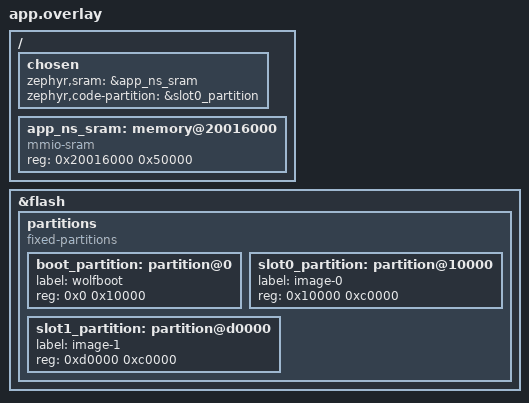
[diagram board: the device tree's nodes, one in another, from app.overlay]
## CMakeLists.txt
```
cmake_minimum_required(VERSION 3.20.0)

# ── wolfBoot module path ───────────────────────────────────────────────────────
if(NOT "$ENV{ZEPHYR_BASE}" STREQUAL "")
    set(_wb_zbase "$ENV{ZEPHYR_BASE}")
elseif(NOT "${ZEPHYR_BASE}" STREQUAL "")
    set(_wb_zbase "${ZEPHYR_BASE}")
else()
    message(FATAL_ERROR
        "ZEPHYR_BASE is not set. "
        "Run cmake with --preset debug or export ZEPHYR_BASE in the environment.")
endif()
get_filename_component(WOLFBOOT_MODULE_DIR
    "${_wb_zbase}/../modules/bootloader/wolfboot" ABSOLUTE)
get_filename_component(_ZEPHYRPROJECT_DIR "${_wb_zbase}/.." ABSOLUTE)

set(_MCUX_ROOT    "${_ZEPHYRPROJECT_DIR}/modules/hal/nxp/mcux/mcux-sdk-ng")
set(_MCUX_CMSIS   "${_ZEPHYRPROJECT_DIR}/modules/hal/cmsis_6/CMSIS")
set(_MCUX_DRV     "${_MCUX_ROOT}/devices/MCX/MCXN/MCXN947")
set(_MCUX_TMPL    "${CMAKE_SOURCE_DIR}/wolfbootConfig")
set(_WOLFSSL_ROOT "${_ZEPHYRPROJECT_DIR}/modules/crypto/wolfssl")

# ── Apply wolfBoot board patch (idempotent, configure time) ───────────────────
set(_WB_PATCH "${CMAKE_SOURCE_DIR}/wolfbootConfig/0001-Update-configs-and-memory-map.patch")
execute_process(
    COMMAND git apply --check --reverse "${_WB_PATCH}"
    WORKING_DIRECTORY "${WOLFBOOT_MODULE_DIR}"
    RESULT_VARIABLE _patch_applied
    OUTPUT_QUIET ERROR_QUIET
)
if(NOT _patch_applied EQUAL 0)
    execute_process(
        COMMAND git apply "${_WB_PATCH}"
        WORKING_DIRECTORY "${WOLFBOOT_MODULE_DIR}"
        RESULT_VARIABLE _patch_result
        ERROR_VARIABLE  _patch_error
    )
    if(NOT _patch_result EQUAL 0)
        message(FATAL_ERROR
            "Failed to apply wolfBoot patch\n"
            "  patch:   ${_WB_PATCH}\n"
            "  workdir: ${WOLFBOOT_MODULE_DIR}\n"
            "  git output: ${_patch_error}")
    endif()
endif()
set(_WB_PATCHES "${_WB_PATCH}")

# wolfBoot cross compiler: CROSS_COMPILE, else the Zephyr SDK, else arm-none-eabi-gcc.
set(_WB_CROSS "")
if(DEFINED ENV{CROSS_COMPILE} AND NOT "$ENV{CROSS_COMPILE}" STREQUAL "")
    set(_WB_CROSS "$ENV{CROSS_COMPILE}")
elseif((DEFINED ENV{ZEPHYR_TOOLCHAIN_VARIANT} AND
        ("$ENV{ZEPHYR_TOOLCHAIN_VARIANT}" STREQUAL "zephyr" OR
         "$ENV{ZEPHYR_TOOLCHAIN_VARIANT}" STREQUAL "zephyr-sdk")) OR
       DEFINED ENV{ZEPHYR_SDK_INSTALL_DIR})
    set(_WB_SDK "$ENV{ZEPHYR_SDK_INSTALL_DIR}")
    # SDK >= 1.0 keeps toolchains in <sdk>/gnu/<triplet>, older ones in <sdk>/<triplet>.
    foreach(_WB_SDK_CANDIDATE
            "${_WB_SDK}/gnu/arm-zephyr-eabi/bin/arm-zephyr-eabi-"
            "${_WB_SDK}/arm-zephyr-eabi/bin/arm-zephyr-eabi-")
        if(EXISTS "${_WB_SDK_CANDIDATE}gcc")
            set(_WB_CROSS "${_WB_SDK_CANDIDATE}")
            break()
        endif()
    endforeach()
    if("${_WB_CROSS}" STREQUAL "")
        message(FATAL_ERROR
            "ZEPHYR_TOOLCHAIN_VARIANT is the Zephyr SDK but no arm-zephyr-eabi "
            "toolchain was found under ZEPHYR_SDK_INSTALL_DIR='${_WB_SDK}'.\n"
            "Install the Zephyr SDK with the arm-zephyr-eabi GNU toolchain, or "
            "set CROSS_COMPILE to a cross compiler prefix.")
    endif()
else()
    find_program(_WB_HOST_GCC arm-none-eabi-gcc)
    if(_WB_HOST_GCC)
        set(_WB_CROSS "arm-none-eabi-")
    else()
        message(FATAL_ERROR
            "No Arm cross compiler for wolfBoot. Either install the Zephyr SDK "
            "(and set ZEPHYR_SDK_INSTALL_DIR, with "
            "ZEPHYR_TOOLCHAIN_VARIANT=zephyr on Zephyr >= 4.3 or zephyr-sdk on "
            "older releases), put arm-none-eabi-gcc in PATH, or set "
            "CROSS_COMPILE. Twister and the Zephyr CI containers both use only "
            "the Zephyr SDK.")
    endif()
endif()
message(STATUS "wolfBoot cross compiler: ${_WB_CROSS}gcc")

# Use the cross strip: the host strip can't handle a Cortex-M33 ELF.
set(_WB_STRIP "strip")
if(DEFINED ENV{CONFIG_STRIP} AND NOT "$ENV{CONFIG_STRIP}" STREQUAL "")
    set(_WB_STRIP "$ENV{CONFIG_STRIP}")
elseif(EXISTS "${_WB_CROSS}strip")
    set(_WB_STRIP "${_WB_CROSS}strip")
endif()
message(STATUS "wolfBoot strip: ${_WB_STRIP}")

# Wipe wolfBoot objects when the compiler or patches change (make only checks timestamps).
set(_WB_STAMP_SRC "${_WB_CROSS}")
foreach(_WB_PATCH IN LISTS _WB_PATCHES)
    file(SHA1 "${_WB_PATCH}" _wb_patch_sha)
    string(APPEND _WB_STAMP_SRC "|${_WB_PATCH}=${_wb_patch_sha}")
endforeach()
string(SHA1 _WB_STAMP "${_WB_STAMP_SRC}")
set(_WB_STAMP_FILE "${WOLFBOOT_MODULE_DIR}/.zephyr-app-build-stamp")
set(_WB_STAMP_OLD "")
if(EXISTS "${_WB_STAMP_FILE}")
    file(READ "${_WB_STAMP_FILE}" _WB_STAMP_OLD)
endif()
if(NOT _WB_STAMP_OLD STREQUAL _WB_STAMP)
    message(STATUS "wolfBoot: toolchain/patches changed, removing stale objects")
    execute_process(
        COMMAND make clean
        WORKING_DIRECTORY "${WOLFBOOT_MODULE_DIR}"
        RESULT_VARIABLE _wb_clean
        OUTPUT_QUIET ERROR_QUIET
    )
    file(GLOB_RECURSE _WB_STALE_OBJS
         "${_MCUX_ROOT}/*.o" "${_MCUX_DRV}/*.o" "${_MCUX_TMPL}/*.o")
    if(_WB_STALE_OBJS)
        list(FILTER _WB_STALE_OBJS EXCLUDE REGEX "${CMAKE_BINARY_DIR}")
        # file(REMOVE) with no arguments errors before CMake 3.31.
        file(REMOVE ${_WB_STALE_OBJS})
    endif()
endif()

# ── wolfBoot binary build (configure time, before Zephyr) ─────────────────────
# CORTEX_M33=1 must be on the command line so the ifeq in arch.mk (~line 357)
# is evaluated true during Makefile parse. arch.mk sets CORTEX_M33=1 for mcxn
# only at ~line 834, which is too late for the parse-time ifeq. Without this,
# -mcmse is never added to CFLAGS and --cmse-implib is never added to
# SECURE_LDFLAGS, so libwolfboot.o lacks SG stubs and wolfboot_tz_nsc.o is
# never emitted by the linker.
# If wolfboot_tz_nsc.o is absent, remove libwolfboot.o (the only object with
# CMSE entry functions) and the stale elf/bin so make recompiles and relinks.
if(NOT EXISTS "${WOLFBOOT_MODULE_DIR}/src/wolfboot_tz_nsc.o")
    file(REMOVE
        "${WOLFBOOT_MODULE_DIR}/src/libwolfboot.o"
        "${WOLFBOOT_MODULE_DIR}/wolfboot.elf"
        "${WOLFBOOT_MODULE_DIR}/wolfboot.bin"
    )
endif()
execute_process(
    COMMAND make wolfboot.bin keytools tools/bin-assemble/bin-assemble
        WOLFBOOT_ROOT=${WOLFBOOT_MODULE_DIR}
        TARGET=mcxn ARCH=ARM TZEN=1 SIGN=ECC384 HASH=SHA384
        CORTEX_M33=1
        CROSS_COMPILE=${_WB_CROSS}
        CONFIG_STRIP=${_WB_STRIP}
        MCUXSDK=1
        # NDEBUG: the MCUX drivers' asserts need stderr/_exit, which a bootloader lacks.
        CFLAGS_EXTRA=-DNDEBUG=1
        MCUXPRESSO=${_MCUX_ROOT}
        MCUXPRESSO_CMSIS=${_MCUX_CMSIS}
        MCUXPRESSO_CPU=MCXN947VDF_cm33_core0
        MCUXPRESSO_DRIVERS=${_MCUX_DRV}
        MCUXPRESSO_PROJECT_TEMPLATE=${_MCUX_TMPL}
        WOLFBOOT_LIB_WOLFSSL=${_WOLFSSL_ROOT}
        NO_MPU=1 NVM_FLASH_WRITEONCE=1 SPMATH=1 RAM_CODE=1 PKA=1 DEBUG_UART=1
        NO_ARM_ASM=1 WOLFBOOT_VERSION=0
        WOLFBOOT_SECTOR_SIZE=0x2000
        WOLFBOOT_KEYVAULT_ADDRESS=0x1000D000 WOLFBOOT_KEYVAULT_SIZE=0
        WOLFBOOT_NSC_ADDRESS=0x1000E000 WOLFBOOT_NSC_SIZE=0x1000
        WOLFBOOT_PARTITION_SIZE=0xC0000
        WOLFBOOT_PARTITION_BOOT_ADDRESS=0x10000
        WOLFBOOT_PARTITION_UPDATE_ADDRESS=0xD0000
        WOLFBOOT_PARTITION_SWAP_ADDRESS=0x190000
        IMAGE_HEADER_SIZE=1024
    WORKING_DIRECTORY "${WOLFBOOT_MODULE_DIR}"
    RESULT_VARIABLE _wb_result
)
if(NOT _wb_result EQUAL 0)
    message(FATAL_ERROR "wolfBoot make failed")
endif()
file(WRITE "${_WB_STAMP_FILE}" "${_WB_STAMP}")

file(MAKE_DIRECTORY "${CMAKE_BINARY_DIR}/zephyr")
file(COPY "${WOLFBOOT_MODULE_DIR}/wolfboot.bin"
          "${WOLFBOOT_MODULE_DIR}/wolfboot.elf"
     DESTINATION "${CMAKE_BINARY_DIR}/zephyr")

# ── Default board + overlay so no CMakePresets.json edit is required ───────────
# This application runs in the non-secure world and is booted by wolfBoot in the
# secure world: it links the wolfBoot NSC veneer (wolfboot_tz_nsc.o), defines
# TZEN, and uses system_init_ns.c. On FRDM-MCXN947 it must be built for the /ns
# board variant -- a secure (non-/ns) build still links and signs, but wolfBoot
# hands off to the wrong memory map / vector table and the app faults at boot
# (garbled UART, never reaches the Zephyr banner). Default board and overlay here
# so the stock build needs no preset edit; an explicit override is still honored
# for porting to other boards.
set(_DEFAULT_BOARD "frdm_mcxn947/mcxn947/cpu0/ns")
set(_SECURE_BOARD  "frdm_mcxn947/mcxn947/cpu0")  # non-bootable secure variant pinned by mistake
if(NOT DEFINED BOARD OR "${BOARD}" STREQUAL "")
    set(BOARD "${_DEFAULT_BOARD}" CACHE STRING "Target board" FORCE)
elseif("${BOARD}" STREQUAL "${_SECURE_BOARD}")
    message(WARNING
        "BOARD='${BOARD}' is the secure variant and will not boot under wolfBoot; "
        "forcing '${_DEFAULT_BOARD}'. (Delete the build dir if it was already "
        "configured for the secure board.)")
    set(BOARD "${_DEFAULT_BOARD}" CACHE STRING "Target board" FORCE)
elseif(NOT "${BOARD}" STREQUAL "${_DEFAULT_BOARD}")
    message(WARNING
        "BOARD='${BOARD}' overrides the default '${_DEFAULT_BOARD}'. On "
        "FRDM-MCXN947 the app is non-secure-world only and a non-/ns build will "
        "not boot under wolfBoot; ignore this if you are porting to another board.")
endif()
if(NOT DEFINED DTC_OVERLAY_FILE OR "${DTC_OVERLAY_FILE}" STREQUAL "")
    set(DTC_OVERLAY_FILE "${CMAKE_SOURCE_DIR}/app.overlay"
        CACHE STRING "Devicetree overlay" FORCE)
endif()

# ── Normal Zephyr app build ───────────────────────────────────────────────────
find_package(Zephyr REQUIRED HINTS $ENV{ZEPHYR_BASE})
project(wolfssl-ota-client)

if(NOT EXISTS "${CMAKE_SOURCE_DIR}/__repo__")
    execute_process(
        COMMAND ${CMAKE_COMMAND} -E create_symlink
            $ENV{ZEPHYR_BASE}/.. ${CMAKE_SOURCE_DIR}/__repo__
        COMMAND_ECHO STDOUT)
endif()

target_sources(app PRIVATE src/main.c)
target_sources(app PRIVATE src/system_init_ns.c)
target_sources(app PRIVATE __repo__/modules/crypto/wolfssl/wolfcrypt/test/test.c)
target_sources(app PRIVATE __repo__/modules/crypto/wolfssl/wolfcrypt/benchmark/benchmark.c)
target_include_directories(app PRIVATE src)

target_sources(app PRIVATE src/mqttClient/fwclient.c)
target_sources(app PRIVATE src/mqttClient/mqttexample.c)
target_sources(app PRIVATE src/mqttClient/mqttnet.c)
target_sources(app PRIVATE src/mqttClient/mqttport.c)
target_include_directories(app PRIVATE src/mqttClient)
target_compile_definitions(app PRIVATE WOLFMQTT_USER_SETTINGS)

add_definitions(-DWOLFSSL_USER_SETTINGS)

target_compile_definitions(app PRIVATE TZEN)
target_link_libraries(app PRIVATE "${WOLFBOOT_MODULE_DIR}/src/wolfboot_tz_nsc.o")
target_include_directories(app PRIVATE "${WOLFBOOT_MODULE_DIR}/include")

# ── Auto strip + sign after every build ───────────────────────────────────────
set(_SIGN_TOOL       "${WOLFBOOT_MODULE_DIR}/tools/keytools/sign")
set(_SIGN_KEY        "${WOLFBOOT_MODULE_DIR}/wolfboot_signing_private_key.der")
set(_ZEPHYR_ELF      "${CMAKE_BINARY_DIR}/zephyr/zephyr.elf")
set(_ZEPHYR_BIN      "${CMAKE_BINARY_DIR}/zephyr/zephyr.bin")
set(_ZEPHYR_STRIPPED "${CMAKE_BINARY_DIR}/zephyr/zephyr_stripped.bin")

add_custom_target(sign_images ALL
    COMMENT "Strip header and sign wolfBoot images (v1, v2)"
    COMMAND ${CMAKE_OBJCOPY}
        --gap-fill 0xFF --output-target=binary
        --remove-section=.comment --remove-section=COMMON
        "${_ZEPHYR_ELF}" "${_ZEPHYR_BIN}"
    COMMAND dd "if=${_ZEPHYR_BIN}" "of=${_ZEPHYR_STRIPPED}" bs=1 skip=1024
    COMMAND ${CMAKE_COMMAND} -E env "IMAGE_HEADER_SIZE=1024"
        "${_SIGN_TOOL}" --ecc384 --sha384 "${_ZEPHYR_STRIPPED}" "${_SIGN_KEY}" 1
    COMMAND ${CMAKE_COMMAND} -E env "IMAGE_HEADER_SIZE=1024"
        "${_SIGN_TOOL}" --ecc384 --sha384 "${_ZEPHYR_STRIPPED}" "${_SIGN_KEY}" 2
    VERBATIM
)
add_dependencies(sign_images zephyr_final)

# ── Factory image (wolfboot + signed app) ─────────────────────────────────────
set(_BIN_ASSEMBLE "${WOLFBOOT_MODULE_DIR}/tools/bin-assemble/bin-assemble")
set(_FACTORY_BIN  "${CMAKE_BINARY_DIR}/zephyr/factory.bin")

add_custom_target(factory_bin ALL
    COMMENT "Assemble factory image: wolfboot at 0x0, signed app at 0x10000"
    COMMAND "${_BIN_ASSEMBLE}"
        "${_FACTORY_BIN}"
        0x0     "${CMAKE_BINARY_DIR}/zephyr/wolfboot.bin"
        0x10000 "${CMAKE_BINARY_DIR}/zephyr/zephyr_stripped_v1_signed.bin"
    VERBATIM
)
add_dependencies(factory_bin sign_images)
```

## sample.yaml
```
sample:
  description: An OTA client that uses the ethernet available on the FRDM-MCXN947 and is
    updated by a wolfBoot secure bootloader
  name: OTA Client with wolfSSL and wolfBoot
tests:
  sample.wolfssl.ota_client:
    # Needs wolfBoot in flash and an MQTT broker, so CI only builds it.
    build_only: true
    tags:
      - net
      - eth
      - tls
      - wolfssl
      - wolfboot
      - ota
    # Boots as /ns under wolfBoot; plain cpu0 is allowed so twister -p cpu0 still builds it.
    platform_allow:
      - frdm_mcxn947/mcxn947/cpu0
      - frdm_mcxn947/mcxn947/cpu0/ns
    integration_platforms:
      - frdm_mcxn947/mcxn947/cpu0/ns
```

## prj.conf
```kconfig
CONFIG_UART_CONSOLE=y

# Link and flash the application into the board-defined code partition
# (slot0_partition at 0x10010000 on FRDM-MCXN947).
CONFIG_USE_DT_CODE_PARTITION=y

# Reserve 0x200 bytes at the start of the code partition for an image header.
CONFIG_ROM_START_OFFSET=0x200

# Linker base remap: use alias addresses instead of physical bus addresses.
CONFIG_FLASH_BASE_ADDRESS=0x0
CONFIG_SRAM_BASE_ADDRESS=0x20016000

# Clock for time()
CONFIG_CLOCK_CONTROL=y

# Log settings. Using immediate mode to not drop bursty logs
CONFIG_LOG=y
CONFIG_LOG_PRINTK=n

# Enable float support for printf/printk
CONFIG_CBPRINTF_FP_SUPPORT=y

CONFIG_MAIN_STACK_SIZE=32768

CONFIG_ASSERT=y

# POSIX Settings
CONFIG_POSIX_API=y

# Network settings
CONFIG_NETWORKING=y
CONFIG_NET_CONFIG_SETTINGS=y
CONFIG_NET_CONFIG_AUTO_INIT=n
CONFIG_NET_CONFIG_NEED_IPV4=n
CONFIG_NET_DHCPV4=n
CONFIG_NET_L2_ETHERNET=y
CONFIG_NET_IPV6=n
CONFIG_NET_CONFIG_NEED_IPV6=n
CONFIG_NET_IPV4=y
CONFIG_NET_SOCKETS=y
CONFIG_NET_TCP=y 
CONFIG_DNS_RESOLVER=y

# Disable Flash API as the flash operations are handled by wolfBoot NSC APIs.
CONFIG_FLASH=n
CONFIG_SOC_FLASH_MCUX=n
# TLS configuration

CONFIG_WOLFSSL=y
CONFIG_WOLFSSL_BUILTIN=y
CONFIG_WOLFSSL_DEBUG=n
# TLS versions are set in src/user_settings.h (the Kconfig ones need no settings file).

# MQTT configuration
CONFIG_WOLFMQTT=y
CONFIG_WOLFMQTT_TLS=y
# Enable wolfMQTT user settings to adjust the configuration as same as wolfSSL
CONFIG_WOLFMQTT_SETTINGS_FILE="user_settings.h"

# CONFIG_NET_BUF_DATA_SIZE=512
CONFIG_NET_BUF_DATA_SIZE=1536

CONFIG_ENTROPY_GENERATOR=y
CONFIG_TEST_RANDOM_GENERATOR=y

#ETHERNET
CONFIG_ETH_NXP_ENET_QOS=y
CONFIG_ETH_NXP_ENET_QOS_MAC=y

CONFIG_WOLFSSL_SETTINGS_FILE="user_settings.h"

# For debug
CONFIG_DEBUG_OPTIMIZATIONS=n

CONFIG_REBOOT=y

# TrustZone settings
# Build this Zephyr image for Non-Secure state execution.
CONFIG_TRUSTED_EXECUTION_SECURE=n
CONFIG_TRUSTED_EXECUTION_NONSECURE=y

# Early SoC init hook: FPU/PowerQuad coprocessor access, ECC, flash cache,
# and aGDET setup for NS world (replaces SystemInit() which now skips NS).
CONFIG_SOC_EARLY_INIT_HOOK=y

# NS board defconfig enables TF-M; this project uses wolfBoot on the secure side.
CONFIG_BUILD_WITH_TFM=n
```

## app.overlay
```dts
/*
 * Upstream cpu0/ns board targets TF-M: chosen points at slot0_ns_partition (256 KiB flash)
 * and non_secure_ram (128 KiB). This app runs under wolfBoot with a different map; see
 * wolfbootConfig/.config and hal/mcxn.c SAU (0x20016000 .. 0x20065FFF).
 */

/ {
	chosen {
		zephyr,sram = &app_ns_sram;
		zephyr,code-partition = &slot0_partition;
	};

	/* NS-visible SRAM for the Zephyr image (must match wolfBoot SAU). */
	app_ns_sram: memory@20016000 {
		compatible = "mmio-sram";
		reg = <0x20016000 0x50000>; /* 320 KiB */
	};
};

/* Drop TF-M flash layout; replace with wolfBoot partition table from wolfbootConfig/.config */
&flash {
	/delete-node/ partitions;
};

&flash {
	partitions {
		compatible = "fixed-partitions";
		#address-cells = <1>;
		#size-cells = <1>;

		boot_partition: partition@0 {
			label = "wolfboot";
			reg = <0x0 0x10000>;
		};

		slot0_partition: partition@10000 {
			label = "image-0";
			reg = <0x10000 0xc0000>;
		};

		slot1_partition: partition@d0000 {
			label = "image-1";
			reg = <0xd0000 0xc0000>;
		};
	};
};
```

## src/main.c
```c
/* main.c
 *
 * Copyright (C) 2006-2024 wolfSSL Inc.
 *
 * This file is part of wolfSSL.
 *
 * wolfSSL is free software; you can redistribute it and/or modify
 * it under the terms of the GNU General Public License as published by
 * the Free Software Foundation; either version 2 of the License, or
 * (at your option) any later version.
 *
 * wolfSSL is distributed in the hope that it will be useful,
 * but WITHOUT ANY WARRANTY; without even the implied warranty of
 * MERCHANTABILITY or FITNESS FOR A PARTICULAR PURPOSE.  See the
 * GNU General Public License for more details.
 *
 * You should have received a copy of the GNU General Public License
 * along with this program; if not, write to the Free Software
 * Foundation, Inc., 51 Franklin Street, Fifth Floor, Boston, MA 02110-1335, USA
 */

/* wolfSSL Includes Start */
/* POSIX socket prototypes come from Zephyr; include them before wolfSSL. */
#include <sys/socket.h>
#include <unistd.h>

#include "user_settings.h"      /* For wolfSSL Zephyr configuration */
#include <wolfssl/wolfcrypt/settings.h>
#include <wolfssl/ssl.h>        /* Basic functionality for TLS */
#include <wolfssl/certs_test.h> /* Needed for Cert Buffers */
#include <wolfssl/wolfcrypt/hash.h>
/* wolfSSL Includes End */

#ifdef WOLFCRYPT_TEST
#include <wolfcrypt/test/test.h>
#endif

#ifdef WOLFCRYPT_BENCHMARK
#include <wolfcrypt/benchmark/benchmark.h>
#endif

/* Standard Packages Start */
#include <stdio.h>
#include <time.h>
#include <string.h>
/* Standard Packages End */

/* Zephyr Includes Start */
#include <zephyr/kernel.h>
#include <zephyr/drivers/gpio.h>
#include <zephyr/net/net_if.h>
#include <zephyr/net/dhcpv4.h>
#include <zephyr/net/net_core.h>
#include <zephyr/net/net_context.h>
#include <zephyr/net/net_mgmt.h>
#include <zephyr/net/net_config.h>
#include <zephyr/net/net_ip.h>
#include <zephyr/sys/reboot.h>
/* Zephyr Includes End */

/* mqttClient Includes Start */
#include "mqttClient/fwclient.h"
/* mqttClient Includes End */

/* wolfBoot Includes Start */
#include "wolfboot/wolfboot.h"
#include "wolfboot_status.h"
/* wolfBoot Includes End */

volatile boot_state_t g_boot_state         = BOOT_STATE_UNKNOWN;
volatile uint32_t     g_boot_version       = 0;
volatile uint32_t     g_update_version     = 0;
volatile uint8_t      g_boot_state_byte    = 0xAA;
volatile int          g_boot_state_rc      = -1;
volatile uint8_t      g_update_state_byte  = 0xAA;
volatile int          g_update_state_rc    = -1;

/* Program Defines Start */

#define DEFAULT_PORT 11111  /* Define the port we want to use for the network */

#define LOCAL_DEBUG 0       /* Use for wolfSSL's internal Debugging */

/* Use DHCP auto IP assignment or static assignment.
 * Follows CONFIG_NET_DHCPV4 from prj.conf so both stay in sync. */
#undef  DHCP_ON
#ifdef CONFIG_NET_DHCPV4
    #define DHCP_ON 1
#else
    #define DHCP_ON 0
#endif
 
#if DHCP_ON == 0
/* Define Static IP, Gateway, and Netmask */
    #define STATIC_IPV4_ADDR  "192.168.1.70"
    #define STATIC_IPV4_GATEWAY "192.168.1.1"
    #define STATIC_IPV4_NETMASK "255.255.255.0"
#endif

/* Set the TLS Version. Currently only 2 or 3 is available for this */
/* application, defaults to TLSv3 */
#undef TLS_VERSION
#define TLS_VERSION 3

/* This sets up the correct function for the application via macros */
#undef TLS_METHOD
#if TLS_VERSION == 3
    #define TLS_METHOD wolfTLSv1_3_server_method()
#elif TLS_VERSION == 2
    #define TLS_METHOD wolfTLSv1_2_server_method()
#else 
    #define TLS_METHOD wolfTLSv1_3_server_method()
#endif

/* Set up the network using the Zephyr network stack */
int startNetwork() {

    struct net_if *iface = net_if_get_default();
    char buf[NET_IPV4_ADDR_LEN];

    #if DHCP_ON == 0
        struct in_addr addr, netmask, gw;
    #endif

    if (!(iface)) { /* See if a network interface (ethernet) is available */
        printf("No network interface determined");
        return 1;
    }

    if (net_if_flag_is_set(iface, NET_IF_DORMANT)) {
        printf("Waiting on network interface to be available");
        while(!net_if_is_up(iface)){
            k_sleep(K_MSEC(100));
        }
    }

    #if DHCP_ON == 1
        printf("\nStarting DHCP to obtain IP address\n");
        net_dhcpv4_start(iface);
        (void)net_mgmt_event_wait_on_iface(iface, NET_EVENT_IPV4_DHCP_BOUND, \
                                            NULL, NULL, NULL, K_FOREVER);
    #elif DHCP_ON == 0
        /* Static IP Configuration */
        if (net_addr_pton(AF_INET, STATIC_IPV4_ADDR, &addr) < 0 ||
            net_addr_pton(AF_INET, STATIC_IPV4_NETMASK, &netmask) < 0 ||
            net_addr_pton(AF_INET, STATIC_IPV4_GATEWAY, &gw) < 0) {
            printf("Invalid IP address settings.\n");
            return -1;
        }
        net_if_ipv4_set_netmask_by_addr(iface, &addr, &netmask);
        net_if_ipv4_set_gw(iface, &gw);
        net_if_ipv4_addr_add(iface, &addr, NET_ADDR_MANUAL, 0);

    #else
        #error "Please set DHCP_ON to true (1) or false (0), if unsure set to true (1)"
    #endif

    /* Display IP address that was assigned when done */
    printf("IP Address is: %s", net_addr_ntop(AF_INET, \
                    &iface->config.ip.ipv4->unicast[0].ipv4.address.in_addr, \
                    buf, sizeof(buf)));

    return 0;
}

/* Initialize Server for a client connection */
int startServer(void) {
    int                sockfd = SOCKET_INVALID;
    int                connd = SOCKET_INVALID;
    struct sockaddr_in servAddr;
    struct sockaddr_in clientAddr;
    socklen_t          size = sizeof(clientAddr);
    char               buff[256];
    size_t             len;
    int                shutdown = 0;
    int                ret;
    const char*        reply = "I hear ya fa shizzle!\n";

    WOLFSSL_CTX* ctx = NULL;
    WOLFSSL*     ssl = NULL;
    WOLFSSL_CIPHER* cipher;

    #if LOCAL_DEBUG
        wolfSSL_Debugging_ON();
    #endif

    wolfSSL_Init();

    /* Create a socket that uses an internet IPv4 address,
     * Sets the socket to be stream based (TCP),
     * 0 means choose the default protocol. */
    if ((sockfd = socket(AF_INET, SOCK_STREAM, 0)) == -1) {
        printf("\nERROR: failed to create the socket\n");
        return 1;
    }

    ctx = wolfSSL_CTX_new(TLS_METHOD);
    if (ctx == NULL) {
        printf("\nERROR: Failed to create WOLFSSL_CTX\n");
        return 1;
    }

    if (wolfSSL_CTX_use_certificate_chain_buffer_format(ctx,
                server_cert_der_2048, sizeof_server_cert_der_2048,
                WOLFSSL_FILETYPE_ASN1) != WOLFSSL_SUCCESS){
        printf("\nERROR: Cannot load server cert buffer\n");
        return 1; 
    }

    if (wolfSSL_CTX_use_PrivateKey_buffer(ctx, server_key_der_2048,
            sizeof_server_key_der_2048, SSL_FILETYPE_ASN1) != WOLFSSL_SUCCESS){
        printf("\nERROR: Can't load server private key buffer");
        return 1;
    }

    /* Initialize the server address struct with zeros */
    memset(&servAddr, 0, sizeof(servAddr));

    /* Fill in the server address */
    servAddr.sin_family      = AF_INET;             /* using IPv4      */
    servAddr.sin_port        = htons(DEFAULT_PORT); /* on DEFAULT_PORT */
    servAddr.sin_addr.s_addr = INADDR_ANY;          /* from anywhere   */

    /* Bind the server socket to our port */
    if (bind(sockfd, (struct sockaddr*)&servAddr, sizeof(servAddr)) == -1) {
        printf("\nERROR: failed to bind\n");
        return 1;
    }

    /* Listen for a new connection, allow 5 pending connections */
    if (listen(sockfd, 5) == -1) {
        printf("\nERROR: failed to listen\n");
        return 1;
    } 

    printf("\nServer Started\n");

    /* Continue to accept clients until shutdown is issued */
    while (!shutdown) {
        printf("Waiting for a connection...\n");

        /* Accept client connections */
        if ((connd = accept(sockfd, (struct sockaddr*)&clientAddr, &size))
            == -1) {
            printf("\nERROR: failed to accept the connection\n");
            return 1;
        }

        /* Create a WOLFSSL object */
        if ((ssl = wolfSSL_new(ctx)) == NULL) {
            printf("\nERROR: failed to create WOLFSSL object\n");
            return 1;
        }

        /* Attach wolfSSL to the socket */
        wolfSSL_set_fd(ssl, connd);

        /* Establish TLS connection */
        ret = wolfSSL_accept(ssl);
        if (ret != WOLFSSL_SUCCESS) {
            printf("\nERROR: wolfSSL_accept error = %d\n",
                wolfSSL_get_error(ssl, ret));
            return 1;
        }


        printf("Client connected successfully\n");

        cipher = wolfSSL_get_current_cipher(ssl);
        printf("SSL cipher suite is %s\n", wolfSSL_CIPHER_get_name(cipher));


        /* Read the client data into our buff array */
        memset(buff, 0, sizeof(buff));
        if ((ret = wolfSSL_read(ssl, buff, sizeof(buff)-1)) == -1) {
            printf("\nERROR: failed to read\n");
            return 1;
        }

        /* Print to stdout any data the client sends */
        printf("Client: %s\n", buff);

        /* Check for server shutdown command */
        if (strncmp(buff, "shutdown", 8) == 0) {
            printf("Shutdown command issued!\n");
            shutdown = 1;
        }



        /* Write our reply into buff */
        memset(buff, 0, sizeof(buff));
        memcpy(buff, reply, strlen(reply));
        len = strnlen(buff, sizeof(buff));

        /* Reply back to the client */
        if ((ret = wolfSSL_write(ssl, buff, len)) != len) {
            printf("\nERROR: failed to write\n");
            return 1;
        }

        /* Notify the client that the connection is ending */
        wolfSSL_shutdown(ssl);
        printf("Shutdown complete\n");

        /* Cleanup after this connection */
        wolfSSL_free(ssl);      /* Free the wolfSSL object              */
        ssl = NULL;
        close(connd);           /* Close the connection to the client   */
    }

    return 0;
}



int main(void)
{
    {
        uint8_t  bst = 0xAA, ust = 0xAA;
        int      brc = wolfBoot_nsc_get_partition_state(PART_BOOT,   &bst);
        int      urc = wolfBoot_nsc_get_partition_state(PART_UPDATE, &ust);
        uint32_t bv  = wolfBoot_nsc_get_image_version(PART_BOOT);
        uint32_t uv  = wolfBoot_nsc_get_image_version(PART_UPDATE);
        boot_state_t cls = boot_state_classify(bv, uv, bst, brc, ust, urc);

        g_boot_version       = bv;
        g_update_version     = uv;
        g_boot_state_byte    = bst;
        g_boot_state_rc      = brc;
        g_update_state_byte  = ust;
        g_update_state_rc    = urc;
        g_boot_state         = cls;

        printf("[wolfBoot] BOOT v=%u state=0x%02x(rc=%d)  UPDATE v=%u state=0x%02x(rc=%d) -> %s\n",
               (unsigned)bv, (unsigned)bst, brc,
               (unsigned)uv, (unsigned)ust, urc,
               boot_state_name(cls));

        if (cls == BOOT_STATE_AWAITING_CONFIRM) {
            printf("[wolfBoot] running new image, will call success() after self-test\n");
            /* Demo: confirm immediately. Real apps should self-test first. */
            wolfBoot_nsc_success();
            g_boot_state = BOOT_STATE_NORMAL;
            printf("[wolfBoot] success() called -> state confirmed\n");
        }
    }

    /* Start up the network */
    if (startNetwork() != 0){
        printf("Network Initialization via DHCP Failed");
        return 1;
    }

#ifdef WOLFCRYPT_TEST
    printf("\nRunning wolfCrypt test\n");
    wolfcrypt_test(NULL);
#endif

#ifdef WOLFCRYPT_BENCHMARK
    printf("\nRunning wolfCrypt benchmark\n");
    benchmark_test(NULL);
#endif

#if defined(CONFIG_WOLFMQTT)
        printf("\nRunning wolfMQTT firmware client for OTA\n");
        if (fwclient_main() != 0) {
            printf("Firmware client has Failed!");
            return 1;
        } else {
            unsigned int irq_key;

            printf("Firmware client completed successfully!\n");

            k_sched_lock();
            irq_key = irq_lock();
            printf("Triggering wolfBoot update\n");
            wolfBoot_nsc_update_trigger();
            irq_unlock(irq_key);
            k_sched_unlock();
            sys_reboot(SYS_REBOOT_COLD);
        }
#else
    if (startServer() != 0){
        printf("Server has Failed!");
        return 1;
    }
#endif
    return 0;
}
```

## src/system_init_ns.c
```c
/*
 * Early SoC initialization for Non-Secure state on MCXN947.
 *
 * soc_reset_hook() in Zephyr's soc.c skips SystemInit() when
 * CONFIG_TRUSTED_EXECUTION_NONSECURE is set, so these initializations
 * are placed here via soc_early_init_hook() instead.
 */

#include <zephyr/platform/hooks.h>
#include "fsl_device_registers.h"

void soc_early_init_hook(void)
{
	/* Enable coprocessor access in Non-Secure state */
#if ((__FPU_PRESENT == 1) && (__FPU_USED == 1))
	SCB->CPACR |= ((3UL << 10*2) | (3UL << 11*2));    /* CP10, CP11 for FPU */
#endif
	SCB->CPACR |= ((3UL << 0*2) | (3UL << 1*2));      /* CP0, CP1 for PowerQuad */

	/* Disable RAM ECC to maximize available memory for Ethernet and app buffers */
	SYSCON->ECC_ENABLE_CTRL = 0;
	SYSCON->NVM_CTRL |= SYSCON_NVM_CTRL_DIS_MBECC_ERR_DATA_MASK;

	/* Disable flash cache */
	SYSCON->NVM_CTRL |= SYSCON_NVM_CTRL_DIS_FLASH_CACHE_MASK;

	/* Disable aGDET interrupt and reset */
	SPC0->ACTIVE_CFG |= SPC_ACTIVE_CFG_GLITCH_DETECT_DISABLE_MASK;
	SPC0->GLITCH_DETECT_SC &= ~SPC_GLITCH_DETECT_SC_LOCK_MASK;
	SPC0->GLITCH_DETECT_SC = 0x3C;
	SPC0->GLITCH_DETECT_SC |= SPC_GLITCH_DETECT_SC_LOCK_MASK;
}
```

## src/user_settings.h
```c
/* user_settings.h
 *
 * Copyright (C) 2006-2026 wolfSSL Inc.
 *
 * This file is part of wolfSSL.
 *
 * wolfSSL is free software; you can redistribute it and/or modify
 * it under the terms of the GNU General Public License as published by
 * the Free Software Foundation; either version 2 of the License, or
 * (at your option) any later version.
 *
 * wolfSSL is distributed in the hope that it will be useful,
 * but WITHOUT ANY WARRANTY; without even the implied warranty of
 * MERCHANTABILITY or FITNESS FOR A PARTICULAR PURPOSE.  See the
 * GNU General Public License for more details.
 *
 * You should have received a copy of the GNU General Public License
 * along with this program; if not, write to the Free Software
 * Foundation, Inc., 51 Franklin Street, Fifth Floor, Boston, MA 02110-1335, USA
 */

#ifndef USER_SETTINGS_H
#define USER_SETTINGS_H

#ifdef __cplusplus
extern "C" {
#endif

/* wolfMQTT feature toggles from Zephyr Kconfig */
#ifdef CONFIG_WOLFMQTT_TLS
    #define ENABLE_MQTT_TLS
#endif


/* ------------------------------------------------------------------------- */
/* Platform */
/* ------------------------------------------------------------------------- */
#define WOLFSSL_GENERAL_ALIGNMENT 4 /* platform requires 32-bit alignment on uint32_t */
#define SIZEOF_LONG_LONG 8          /* long long is 8 bytes / 64-bit */
//#define WOLFSSL_NO_ASM /* optionally disable inline assembly support */
#define WOLFSSL_IGNORE_FILE_WARN /* ignore file includes not required */
//#define WOLFSSL_SMALL_STACK /* option to reduce stack size, offload to heap */
#define BENCH_EMBEDDED /* use smaller buffers in benchmark / tests */

/* Network stack */
/* Default is POSIX sockets */
//#define WOLFSSL_USER_IO /* Use the SetIO callbacks, not the internal wolfio.c socket code */
//#define WOLFSSL_LWIP
//#define WOLFSSL_LWIP_NATIVE
//#define FREERTOS_TCP

/* RTOS */
/* Default is POSIX mutex and pthreads*/
//#define SINGLE_THREADED
//#define FREERTOS
#define NO_FILESYSTEM
#define NO_WRITEV
#define NO_MAIN_FUNCTION
#define NO_MAIN_DRIVER
#define NO_ASN_TIME
#define USE_CERT_BUFFERS_2048
#define USE_ANY_ADDR

//#define WOLFCRYPT_TEST
//#define WOLFCRYPT_BENCHMARK

/* ------------------------------------------------------------------------- */
/* Hardware */
/* ------------------------------------------------------------------------- */
/* CryptoCell support */
#if 0
    //#define WOLFSSL_CRYPTOCELL
    //#define WOLFSSL_CRYPTOCELL_AES
#endif
/* PSA support */
#ifdef CONFIG_MBEDTLS_PSA_CRYPTO_C
    #define WOLFSSL_HAVE_PSA
    #ifndef SINGLE_THREADED
        #define WOLFSSL_PSA_GLOBAL_LOCK
    #endif
    #define WC_NO_HASHDRBG /* use PSA RNG directly via wc_psa_get_random */
#endif

/* ------------------------------------------------------------------------- */
/* FIPS */
/* ------------------------------------------------------------------------- */
#ifdef CONFIG_WOLFCRYPT_FIPS
    /* FIPS Ready */
    #define HAVE_FIPS_VERSION 5
    #define HAVE_FIPS_VERSION_MINOR 3
#endif


/* ------------------------------------------------------------------------- */
/* TLS */
/* ------------------------------------------------------------------------- */
/* TLS v1.2: enabled here, no longer read back from wolfSSL's Kconfig. */
#undef WOLFSSL_NO_TLS12
//#define NO_WOLFSSL_SERVER /* Optionally disable TLS server code */
//#define NO_WOLFSSL_CLIENT /* Optionally disable TLS client code */

/* TLS 1.3 set here: its Kconfig option needs no settings file. */
#define WOLFSSL_TLS13

/* Disable older TLS version prior to 1.2 */
#define NO_OLD_TLS

/* Enable default TLS extensions */
#define HAVE_TLS_EXTENSIONS
#define HAVE_SUPPORTED_CURVES
#define HAVE_EXTENDED_MASTER
#define HAVE_ENCRYPT_THEN_MAC
#define HAVE_SERVER_RENEGOTIATION_INFO
#define HAVE_SNI /* optional Server Name Indicator (SNI) */

/* ASN */
#define WOLFSSL_ASN_TEMPLATE /* use newer ASN template asn.c code (default) */
#if 0 /* optional space reductions */
    #define WOLFSSL_NO_ASN_STRICT
    #define IGNORE_NAME_CONSTRAINTS
#endif

/* Session Cache */
#if 1
    #define SMALL_SESSION_CACHE
    #ifdef WOLFSSL_TLS13
        #define HAVE_SESSION_TICKET /* session tickets required for resumption in TLS v1.3 */
    #endif
#else
    #define NO_SESSION_CACHE /* disable session resumption */
#endif

/* PSK */
#define NO_PSK /* disable pre-shared-key support */


/* ------------------------------------------------------------------------- */
/* Algorithms */
/* ------------------------------------------------------------------------- */
/* RNG */
#ifndef WC_NO_HASHDRBG
    #define HAVE_HASHDRBG /* Use DRBG SHA2-256 and seed */
#endif

/* ECC */
#if 1
    #define HAVE_ECC
    #define ECC_USER_CURVES      /* Enable only ECC curves specific */
    #undef  NO_ECC256            /* Enable SECP256R1 only (on by default) */
    #define NO_ECC192            /* Disable unused curves so preferredGroup[] picks SECP256R1 */
    #define NO_ECC224
    #define NO_ECC384
    #define NO_ECC521
    #define ECC_TIMING_RESISTANT /* Enable Timing Resistance */

    //#define ECC_SHAMIR         /* Optional ECC calculation speed improvement if not using SP implementation */
    //#define WOLFSSL_CUSTOM_CURVES /* enable other curves (not just prime) */
    //#define HAVE_ECC_SECPR2
    //#define HAVE_ECC_SECPR3
    //#define HAVE_ECC_BRAINPOOL
    //#define HAVE_ECC_KOBLITZ
    //#define HAVE_ECC_CDH /* Co-factor */
    //#define HAVE_COMP_KEY /* Compressed key support */
    //#define FP_ECC /* Fixed point caching - speed repeated operations against same key */
    //#define HAVE_ECC_ENCRYPT
    //#define WOLFCRYPT_HAVE_ECCSI
    //#define WOLFSSL_ECDSA_DETERMINISTIC_K_VARIANT
#endif

#define WOLFSSL_OLD_PRIME_CHECK /* Use faster DH prime checking */

/* RSA */
#if 1
    #undef NO_RSA
    #define WC_RSA_BLINDING
    //#define WC_RSA_NO_PADDING
    //#define RSA_LOW_MEM

    #if 0
        #define WOLFSSL_KEY_GEN /* For RSA Key gen only */
    #endif
    #if defined(WOLFSSL_TLS13) || defined(CONFIG_WOLFSSL_RSA_PSS)
        /* TLS v1.3 requires RSA PSS padding */
        #define WC_RSA_PSS
        //#define WOLFSSL_PSS_LONG_SALT
    #endif
#else
    #define NO_RSA
#endif

/* DH */
#if 0
    #undef NO_DH /* on by default */
    #define WOLFSSL_DH_CONST /* don't rely on pow/log */
    #define HAVE_FFDHE_2048
    #define HAVE_FFDHE_3072
    #define HAVE_DH_DEFAULT_PARAMS
    //#define WOLFSSL_DH_EXTRA /* Enable additional DH key import/export */
#else
    #define NO_DH
#endif

/* ChaCha20 / Poly1305 */
#if 1
    #define HAVE_CHACHA
    #define HAVE_POLY1305

    /* Needed for Poly1305 */
    #define HAVE_ONE_TIME_AUTH
#endif

/* Ed25519 / Curve25519 */
#if 0
    #define HAVE_CURVE25519
    #define HAVE_ED25519 /* ED25519 Requires SHA512 */

    /* Optionally use small math (less flash usage, but much slower) */
    //#define CURVED25519_SMALL
#endif

/* SHA-1 */
#if 0
    #undef  NO_SHA /* on by default */
    //#define USE_SLOW_SHA /* 1k smaller, but 25% slower */
#else
    #define NO_SHA
#endif

/* SHA2-256 */
#if 1
    #undef NO_SHA256 /* on by default */
    //#define USE_SLOW_SHA256 /* ~2k smaller and about 25% slower */
    #define WOLFSSL_SHA224
#else
    #define NO_SHA256
#endif

/* SHA2-384/512 */
#if 1
    #define WOLFSSL_SHA384
    #define WOLFSSL_SHA512
    //#define USE_SLOW_SHA512 /* Over twice as small, but 50% slower */
#endif

/* SHA-3 */
#if 1
    #define WOLFSSL_SHA3
#endif

/* AES */
#define HAVE_AES_ECB
/* AES-CBC */
#if 1
    #define HAVE_AES_CBC
#else
    #define NO_AES_CBC
#endif
/* AES-GCM */
#if 1
    #define HAVE_AESGCM
    #define GCM_SMALL /* GCM Method: GCM_TABLE_4BIT, GCM_SMALL, GCM_WORD32 or GCM_TABLE */
    //#define WOLFSSL_AESGCM_STREAM
#endif
//#define HAVE_AES_DECRYPT
//#define WOLFSSL_AES_COUNTER
//#define WOLFSSL_AES_CFB
//#define WOLFSSL_AES_OFB
//#define HAVE_AESCCM
//#define WOLFSSL_AES_XTS

//#define NO_AES_128
//#define NO_AES_192
//#define NO_AES_256
//#define WOLFSSL_AES_SMALL_TABLES
//#define WOLFSSL_AES_NO_UNROLL


/* HKDF */
#if defined(WOLFSSL_TLS13) || defined(CONFIG_WOLFSSL_HKDF)
    #define HAVE_HKDF
#endif

/* CMAC - Zephyr nRF BTLE needs CMAC */
#if 1
    #define WOLFSSL_AES_DIRECT
    #define WOLFSSL_CMAC
#endif


/* Optional Features */
#define WOLFSSL_BASE64_ENCODE /* Enable Base64 encoding */
//#define WC_NO_CACHE_RESISTANT /* systems with cache should enable this for AES, ECC, RSA and DH */
//#define WOLFSSL_CERT_GEN
//#define WOLFSSL_CERT_REQ
//#define WOLFSSL_CERT_EXT
//#define NO_PWDBASED

/* Disable Algorithms */
#define NO_DSA
#define NO_RC4
#define NO_MD4
#define NO_MD5
#define NO_DES3
#define WOLFSSL_NO_SHAKE128
#define WOLFSSL_NO_SHAKE256



/* ------------------------------------------------------------------------- */
/* Math */
/* ------------------------------------------------------------------------- */
/* Math Options */
/* Multi-precision - generic math for all keys sizes and curves */
#if 1
    #define WOLFSSL_SP_MATH /* no multi-precision math, only single */
#elif 1
    /* wolf mp math (sp_int.c) */
    #define WOLFSSL_SP_MATH_ALL /* use SP math for all key sizes and curves */
    //#define WOLFSSL_SP_NO_MALLOC

    /* use smaller version of code */
    #define WOLFSSL_SP_SMALL

    /* Define the maximum math bits used */
    #if !defined(NO_RSA) || !defined(NO_DH)
        #define SP_INT_BITS 2048
    #elif defined(HAVE_ECC)
        #define SP_INT_BITS 256
    #endif

#elif 1
    /* Fast Math (tfm.c) (stack based and timing resistant) */
    #define USE_FAST_MATH
    #define TFM_TIMING_RESISTANT

    /* Define the maximum math bits used (2 * max) */
    #if !defined(NO_RSA) || !defined(NO_DH)
        #define FP_MAX_BITS (2*2048)
        #ifdef HAVE_ECC
            #define ALT_ECC_SIZE /* use heap allocation for ECC point */
        #endif
    #elif defined(HAVE_ECC)
        #define FP_MAX_BITS (2*256)
    #endif
    #ifdef HAVE_ECC
        //#define TFM_ECC256 /* optional speedup for ECC-256 bit */
    #endif
#else
    /* Normal (integer.c) (heap based, not timing resistant) - not recommended */
    #define USE_INTEGER_HEAP_MATH
#endif

/* Single Precision (optional) */
/* Math written for specific curves and key sizes */
#if 1
    #ifdef HAVE_ECC
        #define WOLFSSL_HAVE_SP_ECC
        //#define WOLFSSL_SP_NO_256
        //#define WOLFSSL_SP_384
        //#define WOLFSSL_SP_521
    #endif
    #ifndef NO_RSA
        #define WOLFSSL_HAVE_SP_RSA
        //#define WOLFSSL_SP_NO_2048
        //#define WOLFSSL_SP_NO_3072
        //#define WOLFSSL_SP_4096
    #endif
    #ifndef NO_DH
        #define WOLFSSL_HAVE_SP_DH
    #endif

    #define WOLFSSL_SP_SMALL      /* use smaller version of code */
    //#define WOLFSSL_SP_NO_MALLOC /* disable heap in wolf/SP math */
    //#define SP_DIV_WORD_USE_DIV /* no div64 */

    #if 0
        /* optional speedup with inline assembly */
        //#define WOLFSSL_SP_ARM_CORTEX_M_ASM /* Cortex-M3+ */
        //#define WOLFSSL_SP_ARM_THUMB_ASM    /* Cortex-M0+ thumb */
        //#define WOLFSSL_SP_ARM32_ASM        /* Cortex-R */
        //#define WOLFSSL_SP_ARM64_ASM        /* Cortex-A */
        //#define WOLFSSL_SP_USE_UDIV
    #endif
#endif

/* ------------------------------------------------------------------------- */
/* Assembly Speedups for Symmetric Algorithms */
/* ------------------------------------------------------------------------- */

#ifdef CONFIG_WOLFCRYPT_ARMASM
    #define WOLFSSL_ARMASM
    #define WOLFSSL_NO_HASH_RAW
    #define WOLFSSL_ARMASM_INLINE /* use inline .c versions */
    #define WOLFSSL_ARMASM_NO_NEON

    /* Default is ARMv8 */

    #if 0 /* ARMv7 */
        #define WOLFSSL_ARM_ARCH 7
        #define WOLFSSL_ARMASM_NO_HW_CRYPTO /* enable if processor does not support aes/sha instructions */
    #endif
#endif

#ifdef CONFIG_WOLFCRYPT_INTELASM
    #define USE_INTEL_SPEEDUP
    #define WOLFSSL_X86_64_BUILD /* 64-bit */
    //#define WOLFSSL_X86_BUILD /* 32-bit */

    /* Issues with building AESNI "_mm_aesimc_si128" always_inline */
    //#define WOLFSSL_AESNI
#endif


/* ------------------------------------------------------------------------- */
/* Debugging */
/* ------------------------------------------------------------------------- */
#undef DEBUG_WOLFSSL
#undef NO_ERROR_STRINGS
#ifdef CONFIG_WOLFSSL_DEBUG
    #define DEBUG_WOLFSSL
    #define DEBUG_WOLFMQTT
    #define WOLFMQTT_DEBUG_SOCKET
#else
    #if 1
        #define NO_ERROR_STRINGS
    #endif
#endif


#ifdef __cplusplus
}
#endif

#endif /* USER_SETTINGS_H */
```

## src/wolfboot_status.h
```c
#ifndef WOLFBOOT_STATUS_H
#define WOLFBOOT_STATUS_H

#include <stdint.h>

typedef enum {
    BOOT_STATE_NORMAL,             /* BOOT state SUCCESS, running confirmed image */
    BOOT_STATE_AWAITING_CONFIRM,   /* BOOT state TESTING, app must call success() */
    BOOT_STATE_VERIFY_FAILED,      /* UPDATE state UPDATING + UPDATE>BOOT (sig/integrity) */
    BOOT_STATE_DOWNGRADE_REJECTED, /* UPDATE state UPDATING + UPDATE<BOOT */
    BOOT_STATE_ROLLED_BACK,        /* BOOT state unreadable, UPDATE>BOOT (post-rollback) */
    BOOT_STATE_NO_UPDATE,          /* fresh / no pending update */
    BOOT_STATE_UNKNOWN
} boot_state_t;

static inline const char *boot_state_name(boot_state_t s) {
    switch (s) {
        case BOOT_STATE_NORMAL:             return "NORMAL";
        case BOOT_STATE_AWAITING_CONFIRM:   return "AWAITING_CONFIRM";
        case BOOT_STATE_VERIFY_FAILED:      return "VERIFY_FAILED";
        case BOOT_STATE_DOWNGRADE_REJECTED: return "DOWNGRADE_REJECTED";
        case BOOT_STATE_ROLLED_BACK:        return "ROLLED_BACK";
        case BOOT_STATE_NO_UPDATE:          return "NO_UPDATE";
        default:                            return "UNKNOWN";
    }
}

/* Classify combined state from BOTH partitions:
 *  boot_state  = wolfBoot_get_partition_state(PART_BOOT, ...)
 *  update_state= wolfBoot_get_partition_state(PART_UPDATE, ...)
 * BOOT trailer holds the running image's confirm state (TESTING/SUCCESS).
 * UPDATE trailer holds pending-swap diagnostic (UPDATING when interrupted).
 */
static inline boot_state_t boot_state_classify(
    uint32_t boot_v,  uint32_t update_v,
    uint8_t  boot_state, int boot_rc,
    uint8_t  update_state, int update_rc)
{
    /* 1. BOOT partition state - reveals confirm lifecycle */
    if (boot_rc == 0) {
        if (boot_state == 0x10) return BOOT_STATE_AWAITING_CONFIRM; /* TESTING */
        if (boot_state == 0x00) return BOOT_STATE_NORMAL;           /* SUCCESS */
    }

    /* 2. UPDATE partition UPDATING means swap was started but did not complete */
    if (update_rc == 0 && update_state == 0x70) {
        if (update_v > boot_v) return BOOT_STATE_VERIFY_FAILED;
        if (update_v < boot_v) return BOOT_STATE_DOWNGRADE_REJECTED;
        return BOOT_STATE_UNKNOWN;
    }

    /* 3. No conclusive state info: post-rollback or no update at all */
    if (update_v > boot_v) return BOOT_STATE_ROLLED_BACK;
    return BOOT_STATE_NO_UPDATE;
}

/* Shared globals: filled by main(), read by fwclient publisher */
extern volatile boot_state_t g_boot_state;
extern volatile uint32_t     g_boot_version;
extern volatile uint32_t     g_update_version;
extern volatile uint8_t      g_boot_state_byte;
extern volatile int          g_boot_state_rc;
extern volatile uint8_t      g_update_state_byte;
extern volatile int          g_update_state_rc;

#endif /* WOLFBOOT_STATUS_H */
```
